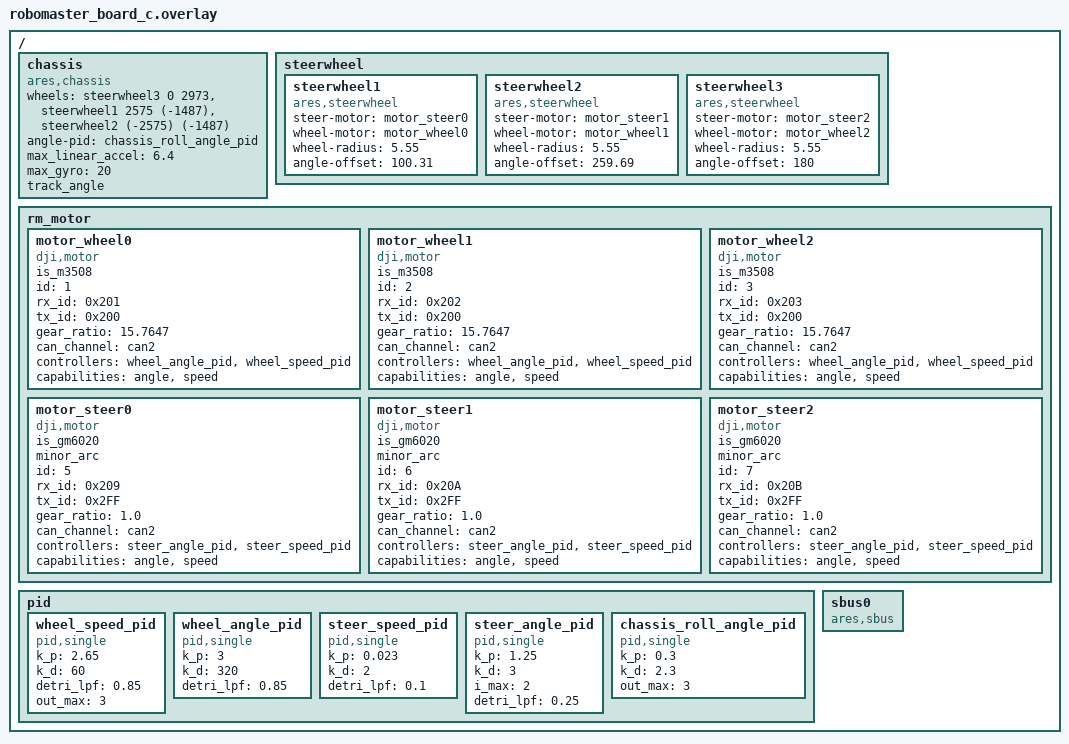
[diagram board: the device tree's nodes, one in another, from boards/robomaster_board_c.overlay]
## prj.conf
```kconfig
# 启用线程分析器
CONFIG_THREAD_ANALYZER=y
CONFIG_THREAD_ANALYZER_USE_LOG=y
CONFIG_THREAD_ANALYZER_USE_PRINTK=n
CONFIG_THREAD_NAME=y
# CONFIG_THREAD_ANALYZER_AUTO=y
# CONFIG_THREAD_ANALYZER_AUTO_INTERVAL=5
CONFIG_THREAD_ANALYZER_LOG_LEVEL_INF=y
CONFIG_THREAD_ANALYZER_AUTO_SEPARATE_CORES=n

# 启用 Shell 支持
CONFIG_SHELL=n
CONFIG_SHELL_BACKENDS=n
CONFIG_SHELL_BACKEND_SERIAL=n

# 启用 UART 控制台
CONFIG_UART_CONSOLE=y

# 禁用 SEGGER RTT
CONFIG_USE_SEGGER_RTT=n

# 启用事件支持
CONFIG_EVENTS=y

# 启用控制台支持
CONFIG_CONSOLE=y

# 启用日志系统
CONFIG_LOG=y
CONFIG_LOG_MODE_IMMEDIATE=y
CONFIG_LOG_PRINTK=y
CONFIG_LOG_BACKEND_UART=y
# CONFIG_LOG_MODE_IMMEDIATE=y

# 启用串行支持
CONFIG_SERIAL=y

# 禁用优化
CONFIG_NO_OPTIMIZATIONS=n

# 启用驱动
CONFIG_MOTOR=y
CONFIG_MOTOR_DJI=y
CONFIG_MOTOR_LOG_LEVEL=4
CONFIG_CAN=y
CONFIG_MOTOR_INIT_PRIORITY=90

CONFIG_ARES=y
CONFIG_ARES_SBUS=y
CONFIG_EKF_LIB=y
CONFIG_VOFA_LIB=y

CONFIG_AUTO_PROBE_GYRO_BIAS=y

# use ASYNC uart API
CONFIG_SERIAL=y
CONFIG_UART_ASYNC_API=y
CONFIG_UART_INTERRUPT_DRIVEN=y

CONFIG_DMA=y
CONFIG_DMA_STM32=y  # STM32 DMA 驱动
CONFIG_UART_STM32=y # STM32 UART 驱动
# CONFIG_STM32_UART_DMA=y

# CONFIG_HAS_STM32CUBE=y
# CONFIG_USE_STM32_HAL_DMA=y
CONFIG_SPI=y
CONFIG_SPI_STM32=y

CONFIG_CMSIS_DSP=y
CONFIG_CMSIS_DSP_MATRIX=y
CONFIG_CMSIS_DSP_CONTROLLER=y
CONFIG_CMSIS_DSP_FASTMATH=y

CONFIG_ZBUS=y
CONFIG_ZBUS_LOG_LEVEL_OFF=y
CONFIG_ZBUS_MSG_SUBSCRIBER=y
CONFIG_ZBUS_RUNTIME_OBSERVERS=y

CONFIG_CHASSIS=y
```

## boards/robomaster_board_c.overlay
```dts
/ {
	chassis: chassis {
		compatible = "ares,chassis";
		status = "okay";
		wheels = <&steerwheel3  0 2973>,
				<&steerwheel1 2575 (-1487)>,
				<&steerwheel2 (-2575) (-1487)>;
		angle-pid = <&chassis_roll_angle_pid>;
		max_linear_accel = "6.4";
		max_gyro = "20";
		track_angle;
	};
	steerwheel {
		steerwheel1: steerwheel1 {
			#wheel-cells = <2>;
			compatible = "ares,steerwheel";
			status = "okay";
			steer-motor = <&motor_steer0>;
			wheel-motor = <&motor_wheel0>;
			wheel-radius = "5.55";
			angle-offset = "100.31";
		};

		steerwheel2: steerwheel2 {
			#wheel-cells = <2>;
			compatible = "ares,steerwheel";
			status = "okay";
			steer-motor = <&motor_steer1>;
			wheel-motor = <&motor_wheel1>;
			wheel-radius = "5.55";
			angle-offset = "259.69";
		};

		steerwheel3: steerwheel3 {
			#wheel-cells = <2>;
			compatible = "ares,steerwheel";
			status = "okay";
			steer-motor = <&motor_steer2>;
			wheel-motor = <&motor_wheel2>;
			wheel-radius = "5.55";
			angle-offset = "180";
		};
	};

	rm_motor {
		motor_wheel0: motor_wheel0{
			compatible = "dji,motor";
            is_m3508;
			id = <1>;
            rx_id = <0x201>;
            tx_id = <0x200>;
			gear_ratio = "15.7647";
			status = "okay";
			can_channel = <&can2>;
			controllers = <&wheel_angle_pid &wheel_speed_pid>;
			capabilities = "angle", "speed";
		};

		motor_wheel1: motor_wheel1{
			compatible = "dji,motor";
            is_m3508;
			id = <2>;
            rx_id = <0x202>;
            tx_id = <0x200>;
			gear_ratio = "15.7647";
			status = "okay";
			can_channel = <&can2>;
			controllers = <&wheel_angle_pid &wheel_speed_pid>;
			capabilities = "angle", "speed";
		};

		motor_wheel2: motor_wheel2{
			compatible = "dji,motor";
            is_m3508;
			id = <3>;
            rx_id = <0x203>;
            tx_id = <0x200>;
			gear_ratio = "15.7647";
			status = "okay";
			can_channel = <&can2>;
			controllers = <&wheel_angle_pid &wheel_speed_pid>;
			capabilities = "angle", "speed";
		};

		motor_steer0: motor_steer0{
			compatible = "dji,motor";
			is_gm6020;
			minor_arc; // 必须配置此选项使之走劣弧
			id = <5>;
			rx_id = <0x209>;
			tx_id = <0x2FF>;
			gear_ratio = "1.0";
			status = "okay";
			can_channel = <&can2>;
			controllers = <&steer_angle_pid &steer_speed_pid>;
			capabilities = "angle", "speed";
		};

		motor_steer1: motor_steer1{
			compatible = "dji,motor";
			is_gm6020;
			minor_arc; // 必须配置此选项使之走劣弧
			id = <6>;
			rx_id = <0x20A>;
			tx_id = <0x2FF>;
			gear_ratio = "1.0";
			status = "okay";
			can_channel = <&can2>;
			controllers = <&steer_angle_pid &steer_speed_pid>;
			capabilities = "angle", "speed";
		};

		motor_steer2: motor_steer2{
			compatible = "dji,motor";
			is_gm6020;
			minor_arc; // 必须配置此选项使之走劣弧
			id = <7>;
			rx_id = <0x20B>;
			tx_id = <0x2FF>;
			gear_ratio = "1.0";
			status = "okay";
			can_channel = <&can2>;
			controllers = <&steer_angle_pid &steer_speed_pid>;
			capabilities = "angle", "speed";
		};
	};

	pid {
		wheel_speed_pid: wheel_speed_pid {
			#controller-cells = <0>;
			compatible = "pid,single";
			k_p = "2.65";
			k_d = "60";
			detri_lpf = "0.85";
			out_max = "3";
		};

		wheel_angle_pid: wheel_angle_pid {
			#controller-cells = <0>;
			compatible = "pid,single";
			k_p = "3";
			k_d = "320";
			detri_lpf = "0.85";
		};

		steer_speed_pid: steer_speed_pid {
			#controller-cells = <0>;
			compatible = "pid,single";
			k_p = "0.023";
			k_d = "2";
			detri_lpf = "0.1";
		};

		steer_angle_pid: steer_angle_pid {
			#controller-cells = <0>;
			compatible = "pid,single";
			k_p = "1.25";
			k_d = "3";
			i_max = "2";
			detri_lpf = "0.25";
		};

		chassis_roll_angle_pid: chassis_roll_angle_pid {
			#controller-cells = <0>;
			compatible = "pid,single";
			k_p = "0.3";
			k_d = "2.3";
			out_max = "3";
		};
	};
	
	sbus0: sbus0 {
		compatible = "ares,sbus";
		status = "okay";
	};
};
```

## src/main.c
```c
/*
 * Copyright (c) 2024 ttwards <12411711@mail.sustech.edu.cn>
 *
 * SPDX-License-Identifier: Apache-2.0
 */

#include <math.h>
#include <stddef.h>
#include <stdint.h>
#include <string.h>
#include <zephyr/device.h>
#include <zephyr/logging/log.h>
#include <zephyr/kernel.h>
#include <zephyr/drivers/motor.h>
#include <zephyr/drivers/sbus.h>
#include <ares/board/init.h>
#include <ares/ekf/imu_task.h>
#include "devices.h"
#include <zephyr/drivers/chassis.h>

LOG_MODULE_REGISTER(main, LOG_LEVEL_DBG);

/* CAN Feedback to console*/
void console_feedback(void *arg1, void *arg2, void *arg3)
{
	float angle = 0;
	int n = 0;
	while (1) {
		float X = sbus_get_percent(sbus, 3);
		float Y = sbus_get_percent(sbus, 1);

		chassis_set_speed(chassis, X * 7, Y * 7);
		chassis_set_gyro(chassis, -sbus_get_percent(sbus, 0) * 2.0f);

		k_msleep(20);
	}
}
K_THREAD_DEFINE(feedback_thread, 4096, console_feedback, NULL, NULL, NULL, 1, 0, 100);

int pub_cnt = 0;

int main(void)
{

	k_sleep(K_MSEC(50));
	chassis_set_enabled(chassis, false);
	IMU_Sensor_trig_init(accel_dev, gyro_dev);
	chassis_set_enabled(chassis, true);

	IMU_Sensor_set_update_cb(Sensor_update_cb);

	chassis_set_angle(chassis, 0);

	while (1) {
		k_sleep(K_MSEC(500));
	}
}
```

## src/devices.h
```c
#include <zephyr/device.h>

/* Devicetree */
#define UART_NODE DT_ALIAS(vofa)
const struct device *uart_dev = DEVICE_DT_GET(UART_NODE);

#define ACCEL_NODE DT_NODELABEL(bmi08x_accel)
const struct device *accel_dev = DEVICE_DT_GET(ACCEL_NODE);

#define GYRO_NODE DT_NODELABEL(bmi08x_gyro)
const struct device *gyro_dev = DEVICE_DT_GET(GYRO_NODE);

#define WHEELMOTOR1_NODE DT_NODELABEL(motor_wheel0)
#define WHEELMOTOR2_NODE DT_NODELABEL(motor_wheel1)
#define WHEELMOTOR3_NODE DT_NODELABEL(motor_wheel2)

#define STEERMOTOR1_NODE DT_NODELABEL(motor_steer0)
#define STEERMOTOR2_NODE DT_NODELABEL(motor_steer1)
#define STEERMOTOR3_NODE DT_NODELABEL(motor_steer2)

#define CHASSIS_NODE DT_NODELABEL(chassis)

const struct device *wheel_motor1 = DEVICE_DT_GET(WHEELMOTOR1_NODE);
const struct device *wheel_motor2 = DEVICE_DT_GET(WHEELMOTOR2_NODE);
const struct device *wheel_motor3 = DEVICE_DT_GET(WHEELMOTOR3_NODE);

const struct device *steer_motor1 = DEVICE_DT_GET(STEERMOTOR1_NODE);
const struct device *steer_motor2 = DEVICE_DT_GET(STEERMOTOR2_NODE);
const struct device *steer_motor3 = DEVICE_DT_GET(STEERMOTOR3_NODE);

const struct device *chassis = DEVICE_DT_GET(CHASSIS_NODE);

#define SBUS_NODE DT_NODELABEL(sbus0)
const struct device *sbus = DEVICE_DT_GET(SBUS_NODE);
```
